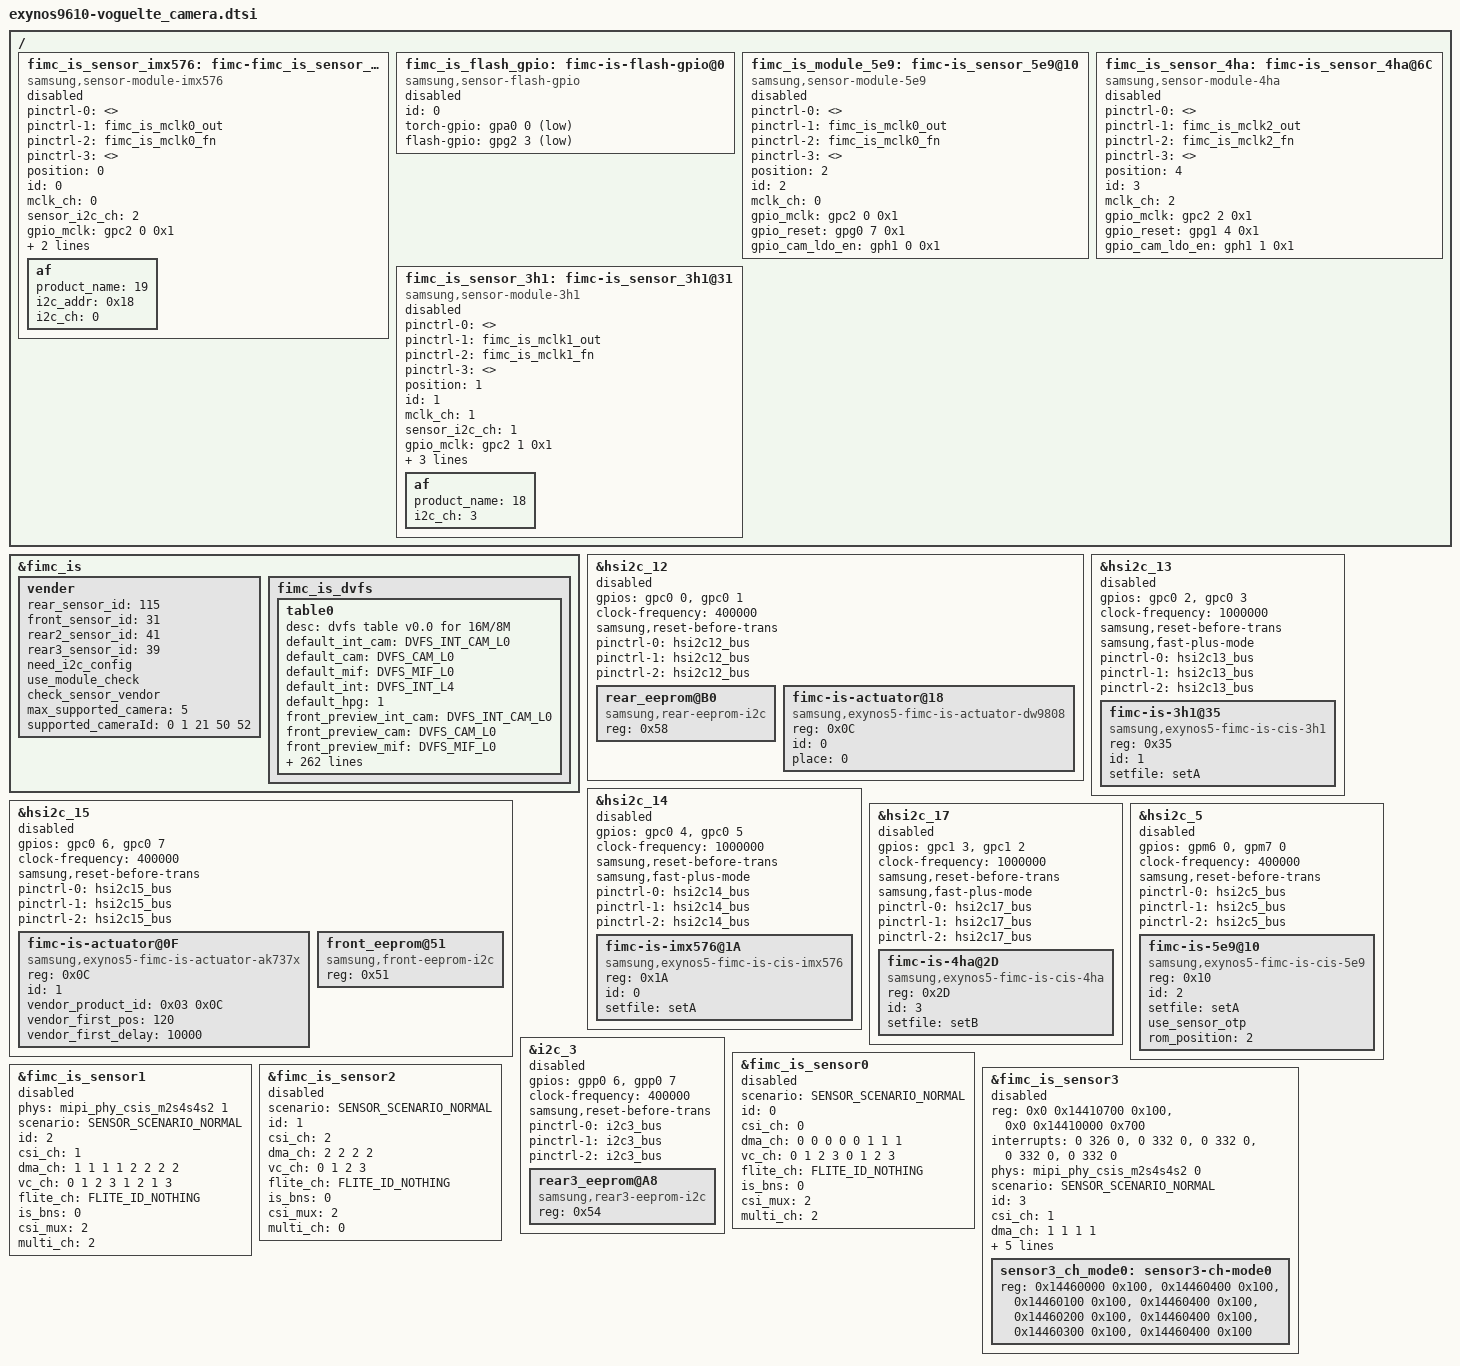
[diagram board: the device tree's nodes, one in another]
/*
 * SAMSUNG EXYNOS9610 board camera device tree source
 *
 * Copyright (c) 2018 Samsung Electronics Co., Ltd.
 *		http://www.samsung.com
 *
 * This program is free software; you can redistribute it and/or modify
 * it under the terms of the GNU General Public License version 2 as
 * published by the Free Software Foundation.
 */

#include <dt-bindings/camera/fimc_is.h>

/ {
	fragment@camera {
		target-path = "/";
		__overlay__ {
			/* REAR CAMERA */
			fimc_is_sensor_imx576: fimc-fimc_is_sensor_imx576@1A {
				compatible = "samsung,sensor-module-imx576";

				pinctrl-names = "pin0", "pin1", "pin2", "release";
				pinctrl-0 = <>;
				pinctrl-1 = <&fimc_is_mclk0_out>;
				pinctrl-2 = <&fimc_is_mclk0_fn>;
				pinctrl-3 = <>;

				position = <0>;	/* Rear:0. Front:1. Rear_sub:2. Secure:3. */
				id = <0>; /* fimc_is_sensor id */
				mclk_ch = <0>;
				sensor_i2c_ch = <2>; /* SENSOR_CONTROL_I2C2 */

				gpio_mclk = <&gpc2 0 0x1>;
				gpio_reset = <&gpg1 1 0x1>; /* sensor reset */
				gpio_camcore_1p05_en = <&gpc1 1 0x1>; /* gpio_camcore_1p05_en */

				status = "disabled";

				af {
					product_name = <19>;			/* ACTUATOR_NAME_DW9808 */
					i2c_addr = <0x18>;
					i2c_ch = <0>;					/* SENSOR_CONTROL_I2C0 */
				};
			};

			fimc_is_flash_gpio: fimc-is-flash-gpio@0 {
				compatible = "samsung,sensor-flash-gpio";
				id = <0>;
				status = "disabled";

				torch-gpio = <&gpa0 0 0x1>;
				flash-gpio = <&gpg2 3 0x1>;
			};

			/* REAR Sub CAMERA */
			fimc_is_module_5e9: fimc-is_sensor_5e9@10 {
				compatible = "samsung,sensor-module-5e9";

				pinctrl-names = "pin0", "pin1", "pin2", "release";
				pinctrl-0 = <>;
				pinctrl-1 = <&fimc_is_mclk0_out>;
				pinctrl-2 = <&fimc_is_mclk0_fn>;
				pinctrl-3 = <>;

				position = <2>;	/* Rear:0. Front:1 */
				id = <2>; /* fimc_is_sensor id */
				mclk_ch = <0>;

				gpio_mclk = <&gpc2 0 0x1>;		/* RCAM1_RCAM2_MCLK */
				gpio_reset = <&gpg0 7 0x1>;		/* RCAM2_RST_N */
				gpio_cam_ldo_en = <&gph1 0 0x1>;	/* RCAM2_LDO_EN  ---> DVDD1P2, AVDD2P8, VDDIO1P8 */
				status = "disabled";
			};

			/* REAR Third CAMERA */
			fimc_is_sensor_4ha: fimc-is_sensor_4ha@6C {
				compatible = "samsung,sensor-module-4ha";

				pinctrl-names = "pin0", "pin1", "pin2", "release";
				pinctrl-0 = <>;
				pinctrl-1 = <&fimc_is_mclk2_out>;
				pinctrl-2 = <&fimc_is_mclk2_fn>;
				pinctrl-3 = <>;

				position = <4>;	/* Rear:0. Front:1 .. Rear3:6*/
				id = <3>;		/* fimc_is_sensor id */
				mclk_ch = <2>;

				gpio_mclk = <&gpc2 2 0x1>;		/* RCAM3_MCLK */
				gpio_reset = <&gpg1 4 0x1>;		/* RCAM3_RST_N */
				gpio_cam_ldo_en = <&gph1 1 0x1>;	/* RCAM3_LDO_EN  ---> DVDD1P2, AVDD2P8, VDDIO1P8 */
				status = "disabled";
			};

			/* FRONT CAMERA */
			fimc_is_sensor_3h1: fimc-is_sensor_3h1@31 {
				compatible = "samsung,sensor-module-3h1";

				pinctrl-names = "pin0", "pin1", "pin2", "release";
				pinctrl-0 = <>;
				pinctrl-1 = <&fimc_is_mclk1_out>;
				pinctrl-2 = <&fimc_is_mclk1_fn>;
				pinctrl-3 = <>;

				position = <1>;	/* Rear:0. Front:1. Rear_sub:2. Secure:3. */
				id = <1>; /* fimc_is_sensor id */
				mclk_ch = <1>;
				sensor_i2c_ch = <1>; /* SENSOR_CONTROL_I2C1 */

				gpio_mclk = <&gpc2 1 0x1>;
				gpio_reset = <&gpg1 7 0x1>; /* sensor reset */
				gpio_cam_ldo_en = <&gpc1 0 0x1>; /* CAM LDO all enable */

				power_seq_id = <1>;
				status = "disabled";

				af {
					product_name = <18>; /* ACTUATOR_NAME_AK737X : ak7372 */
					i2c_ch = <3>; /* SENSOR_CONTROL_I2C3 */
				};

			};

		}; /* end of __overlay__ */
	}; /* end of fragment */
}; /* end of root */

/***** reference symbol node *****/

&fimc_is {
	vender {
		rear_sensor_id = <115>; /* SENSOR_NAME_IMX576 */
		front_sensor_id = <31>; /* SENSOR_NAME_S5K3H1 */
		rear2_sensor_id = <41>; /* SENSOR_NAME_S5K5E9  */
		rear3_sensor_id = <39>;	/* SENSOR_NAME_S5K4HA */
		need_i2c_config;
		use_module_check;
		check_sensor_vendor;
		max_supported_camera = <5>;
		supported_cameraId = <0 1 21 50 52>;
	};

	fimc_is_dvfs {
		#define DVFS_INT_CAM_L0 690000
		#define DVFS_INT_CAM_L1 680000
		#define DVFS_INT_CAM_L2 670000
		#define DVFS_INT_CAM_L3 660000
		#define DVFS_INT_CAM_L4 650000

		#define DVFS_INT_L0 667000
		#define DVFS_INT_L1 533000
		#define DVFS_INT_L2 400000
		#define DVFS_INT_L3 200000
		#define DVFS_INT_L4 100000

		#define DVFS_CAM_L0 690000
		#define DVFS_CAM_L1 680000
		#define DVFS_CAM_L2 670000
		#define DVFS_CAM_L3 660000
		#define DVFS_CAM_L4 650000
		#define DVFS_CAM_L5 640000

		#define DVFS_MIF_L0 2093000
		#define DVFS_MIF_L1 2002000
		#define DVFS_MIF_L2 1794000
		#define DVFS_MIF_L3 1539000
		#define DVFS_MIF_L4 1352000
		#define DVFS_MIF_L5 1014000
		#define DVFS_MIF_L6 845000
		#define DVFS_MIF_L7 676000
		#define DVFS_MIF_L8 546000
		#define DVFS_MIF_L9 419000

		table0 {
			desc = "dvfs table v0.0 for 16M/8M";

			default_int_cam = <DVFS_INT_CAM_L0>;
			default_cam = <DVFS_CAM_L0>;
			default_mif = <DVFS_MIF_L0>;
			default_int = <DVFS_INT_L4>;
			default_hpg = <1>;

			front_preview_int_cam = <DVFS_INT_CAM_L0>;
			front_preview_cam = <DVFS_CAM_L0>;
			front_preview_mif = <DVFS_MIF_L0>;
			front_preview_int = <DVFS_INT_L4>;
			front_preview_hpg = <1>;

			front_preview_full_int_cam = <DVFS_INT_CAM_L0>;
			front_preview_full_cam = <DVFS_CAM_L0>;
			front_preview_full_mif = <DVFS_MIF_L0>;
			front_preview_full_int = <DVFS_INT_L4>;
			front_preview_full_hpg = <1>;

			front_capture_int_cam = <DVFS_INT_CAM_L0>;
			front_capture_cam = <DVFS_CAM_L0>;
			front_capture_mif = <DVFS_MIF_L0>;
			front_capture_int = <DVFS_INT_L4>;
			front_capture_hpg = <1>;

			front_video_int_cam = <DVFS_INT_CAM_L0>;
			front_video_cam = <DVFS_CAM_L0>;
			front_video_mif = <DVFS_MIF_L0>;
			front_video_int = <DVFS_INT_L4>;
			front_video_hpg = <1>;

			front_video_capture_int_cam = <DVFS_INT_CAM_L0>;
			front_video_capture_cam = <DVFS_CAM_L0>;
			front_video_capture_mif = <DVFS_MIF_L0>;
			front_video_capture_int = <DVFS_INT_L4>;
			front_video_capture_hpg = <1>;

			front_wide_selfie_int_cam = <DVFS_INT_CAM_L0>;
			front_wide_selfie_cam = <DVFS_CAM_L0>;
			front_wide_selfie_mif = <DVFS_MIF_L0>;
			front_wide_selfie_int = <DVFS_INT_L4>;
			front_wide_selfie_hpg = <1>;

			front_vt1_int_cam = <DVFS_INT_CAM_L0>;
			front_vt1_cam = <DVFS_CAM_L0>;
			front_vt1_mif = <DVFS_MIF_L0>;
			front_vt1_int = <DVFS_INT_L4>;
			front_vt1_hpg = <1>;

			front_vt2_int_cam = <DVFS_INT_CAM_L0>;
			front_vt2_cam = <DVFS_CAM_L0>;
			front_vt2_mif = <DVFS_MIF_L0>;
			front_vt2_int = <DVFS_INT_L4>;
			front_vt2_hpg = <1>;

			front_vt4_int_cam = <DVFS_INT_CAM_L0>;
			front_vt4_cam = <DVFS_CAM_L0>;
			front_vt4_mif = <DVFS_MIF_L0>;
			front_vt4_int = <DVFS_INT_L4>;
			front_vt4_hpg = <1>;

			rear2_preview_fhd_int_cam = <DVFS_INT_CAM_L0>;
			rear2_preview_fhd_cam = <DVFS_CAM_L0>;
			rear2_preview_fhd_mif = <DVFS_MIF_L0>;
			rear2_preview_fhd_int = <DVFS_INT_L4>;
			rear2_preview_fhd_hpg = <1>;

			rear2_capture_int_cam = <DVFS_INT_CAM_L0>;
			rear2_capture_cam = <DVFS_CAM_L0>;
			rear2_capture_mif = <DVFS_MIF_L0>;
			rear2_capture_int = <DVFS_INT_L4>;
			rear2_capture_hpg = <1>;

			rear2_video_fhd_int_cam = <DVFS_INT_CAM_L0>;
			rear2_video_fhd_cam = <DVFS_CAM_L0>;
			rear2_video_fhd_mif = <DVFS_MIF_L0>;
			rear2_video_fhd_int = <DVFS_INT_L4>;
			rear2_video_fhd_hpg = <1>;

			rear2_video_fhd_capture_int_cam = <DVFS_INT_CAM_L0>;
			rear2_video_fhd_capture_cam = <DVFS_CAM_L0>;
			rear2_video_fhd_capture_mif = <DVFS_MIF_L0>;
			rear2_video_fhd_capture_int = <DVFS_INT_L4>;
			rear2_video_fhd_capture_hpg = <1>;

			rear3_preview_int_cam = <DVFS_INT_CAM_L0>;
			rear3_preview_cam = <DVFS_CAM_L0>;
			rear3_preview_mif = <DVFS_MIF_L0>;
			rear3_preview_int = <DVFS_INT_L4>;
			rear3_preview_hpg = <1>;

			rear3_capture_int_cam = <DVFS_INT_CAM_L0>;
			rear3_capture_cam = <DVFS_CAM_L0>;
			rear3_capture_mif = <DVFS_MIF_L0>;
			rear3_capture_int = <DVFS_INT_L4>;
			rear3_capture_hpg = <1>;

			rear3_video_int_cam = <DVFS_INT_CAM_L0>;
			rear3_video_cam = <DVFS_CAM_L0>;
			rear3_video_mif = <DVFS_MIF_L0>;
			rear3_video_int = <DVFS_INT_L4>;
			rear3_video_hpg = <1>;

			rear_preview_fhd_int_cam = <DVFS_INT_CAM_L0>;
			rear_preview_fhd_cam = <DVFS_CAM_L0>;
			rear_preview_fhd_mif = <DVFS_MIF_L0>;
			rear_preview_fhd_int = <DVFS_INT_L4>;
			rear_preview_fhd_hpg = <1>;

			rear_preview_hd_int_cam = <DVFS_INT_CAM_L0>;
			rear_preview_hd_cam = <DVFS_CAM_L0>;
			rear_preview_hd_mif = <DVFS_MIF_L0>;
			rear_preview_hd_int = <DVFS_INT_L4>;
			rear_preview_hd_hpg = <1>;

			rear_preview_uhd_int_cam = <DVFS_INT_CAM_L0>;
			rear_preview_uhd_cam = <DVFS_CAM_L0>;
			rear_preview_uhd_mif = <DVFS_MIF_L0>;
			rear_preview_uhd_int = <DVFS_INT_L4>;
			rear_preview_uhd_hpg = <1>;

			rear_preview_full_int_cam = <DVFS_INT_CAM_L0>;
			rear_preview_full_cam = <DVFS_CAM_L0>;
			rear_preview_full_mif = <DVFS_MIF_L0>;
			rear_preview_full_int = <DVFS_INT_L4>;
			rear_preview_full_hpg = <1>;

			rear_capture_int_cam = <DVFS_INT_CAM_L0>;
			rear_capture_cam = <DVFS_CAM_L0>;
			rear_capture_mif = <DVFS_MIF_L0>;
			rear_capture_int = <DVFS_INT_L4>;
			rear_capture_hpg = <1>;

			rear_video_fhd_int_cam = <DVFS_INT_CAM_L0>;
			rear_video_fhd_cam = <DVFS_CAM_L0>;
			rear_video_fhd_mif = <DVFS_MIF_L0>;
			rear_video_fhd_int = <DVFS_INT_L4>;
			rear_video_fhd_hpg = <1>;

			rear_video_hd_int_cam = <DVFS_INT_CAM_L0>;
			rear_video_hd_cam = <DVFS_CAM_L0>;
			rear_video_hd_mif = <DVFS_MIF_L0>;
			rear_video_hd_int = <DVFS_INT_L4>;
			rear_video_hd_hpg = <1>;

			rear_video_uhd_int_cam = <DVFS_INT_CAM_L0>;
			rear_video_uhd_cam = <DVFS_CAM_L0>;
			rear_video_uhd_mif = <DVFS_MIF_L0>;
			rear_video_uhd_int = <DVFS_INT_L4>;
			rear_video_uhd_hpg = <1>;

			rear_video_fhd_capture_int_cam = <DVFS_INT_CAM_L0>;
			rear_video_fhd_capture_cam = <DVFS_CAM_L0>;
			rear_video_fhd_capture_mif = <DVFS_MIF_L0>;
			rear_video_fhd_capture_int = <DVFS_INT_L4>;
			rear_video_fhd_capture_hpg = <1>;

			rear_video_hd_capture_int_cam = <DVFS_INT_CAM_L0>;
			rear_video_hd_capture_cam = <DVFS_CAM_L0>;
			rear_video_hd_capture_mif = <DVFS_MIF_L0>;
			rear_video_hd_capture_int = <DVFS_INT_L4>;
			rear_video_hd_capture_hpg = <1>;

			rear_video_uhd_capture_int_cam = <DVFS_INT_CAM_L0>;
			rear_video_uhd_capture_cam = <DVFS_CAM_L0>;
			rear_video_uhd_capture_mif = <DVFS_MIF_L0>;
			rear_video_uhd_capture_int = <DVFS_INT_L4>;
			rear_video_uhd_capture_hpg = <1>;

			dual_preview_int_cam = <DVFS_INT_CAM_L0>;
			dual_preview_cam = <DVFS_CAM_L0>;
			dual_preview_mif = <DVFS_MIF_L0>;
			dual_preview_int = <DVFS_INT_L4>;
			dual_preview_hpg = <1>;

			dual_capture_int_cam = <DVFS_INT_CAM_L0>;
			dual_capture_cam = <DVFS_CAM_L0>;
			dual_capture_mif = <DVFS_MIF_L0>;
			dual_capture_int = <DVFS_INT_L4>;
			dual_capture_hpg = <1>;

			dual_video_fhd_int_cam = <DVFS_INT_CAM_L0>;
			dual_video_fhd_cam = <DVFS_CAM_L0>;
			dual_video_fhd_mif = <DVFS_MIF_L0>;
			dual_video_fhd_int = <DVFS_INT_L4>;
			dual_video_fhd_hpg = <1>;

			dual_video_fhd_capture_int_cam = <DVFS_INT_CAM_L0>;
			dual_video_fhd_capture_cam = <DVFS_CAM_L0>;
			dual_video_fhd_capture_mif = <DVFS_MIF_L0>;
			dual_video_fhd_capture_int = <DVFS_INT_L4>;
			dual_video_fhd_capture_hpg = <1>;

			dual_video_uhd_int_cam = <DVFS_INT_CAM_L0>;
			dual_video_uhd_cam = <DVFS_CAM_L0>;
			dual_video_uhd_mif = <DVFS_MIF_L0>;
			dual_video_uhd_int = <DVFS_INT_L4>;
			dual_video_uhd_hpg = <1>;

			dual_video_uhd_capture_int_cam = <DVFS_INT_CAM_L0>;
			dual_video_uhd_capture_cam = <DVFS_CAM_L0>;
			dual_video_uhd_capture_mif = <DVFS_MIF_L0>;
			dual_video_uhd_capture_int = <DVFS_INT_L4>;
			dual_video_uhd_capture_hpg = <1>;

			dual_sync_preview_int_cam = <DVFS_INT_CAM_L0>;
			dual_sync_preview_cam = <DVFS_CAM_L0>;
			dual_sync_preview_mif = <DVFS_MIF_L0>;
			dual_sync_preview_int = <DVFS_INT_L4>;
			dual_sync_preview_hpg = <1>;

			dual_sync_capture_int_cam = <DVFS_INT_CAM_L0>;
			dual_sync_capture_cam = <DVFS_CAM_L0>;
			dual_sync_capture_mif = <DVFS_MIF_L0>;
			dual_sync_capture_int = <DVFS_INT_L4>;
			dual_sync_capture_hpg = <1>;

			dual_sync_preview_whd_int_cam = <DVFS_INT_CAM_L0>;
			dual_sync_preview_whd_cam = <DVFS_CAM_L0>;
			dual_sync_preview_whd_mif = <DVFS_MIF_L0>;
			dual_sync_preview_whd_int = <DVFS_INT_L4>;
			dual_sync_preview_whd_hpg = <1>;

			dual_sync_whd_capture_int_cam = <DVFS_INT_CAM_L0>;
			dual_sync_whd_capture_cam = <DVFS_CAM_L0>;
			dual_sync_whd_capture_mif = <DVFS_MIF_L0>;
			dual_sync_whd_capture_int = <DVFS_INT_L4>;
			dual_sync_whd_capture_hpg = <1>;

			dual_sync_video_fhd_int_cam = <DVFS_INT_CAM_L0>;
			dual_sync_video_fhd_cam = <DVFS_CAM_L0>;
			dual_sync_video_fhd_mif = <DVFS_MIF_L0>;
			dual_sync_video_fhd_int = <DVFS_INT_L4>;
			dual_sync_video_fhd_hpg = <1>;

			dual_sync_video_fhd_capture_int_cam = <DVFS_INT_CAM_L0>;
			dual_sync_video_fhd_capture_cam = <DVFS_CAM_L0>;
			dual_sync_video_fhd_capture_mif = <DVFS_MIF_L0>;
			dual_sync_video_fhd_capture_int = <DVFS_INT_L4>;
			dual_sync_video_fhd_capture_hpg = <1>;

			dual_sync_video_uhd_int_cam = <DVFS_INT_CAM_L0>;
			dual_sync_video_uhd_cam = <DVFS_CAM_L0>;
			dual_sync_video_uhd_mif = <DVFS_MIF_L0>;
			dual_sync_video_uhd_int = <DVFS_INT_L4>;
			dual_sync_video_uhd_hpg = <1>;

			dual_sync_video_uhd_capture_int_cam = <DVFS_INT_CAM_L0>;
			dual_sync_video_uhd_capture_cam = <DVFS_CAM_L0>;
			dual_sync_video_uhd_capture_mif = <DVFS_MIF_L0>;
			dual_sync_video_uhd_capture_int = <DVFS_INT_L4>;
			dual_sync_video_uhd_capture_hpg = <1>;

			secure_front_int_cam = <DVFS_INT_CAM_L0>;
			secure_front_cam = <DVFS_CAM_L0>;
			secure_front_mif = <DVFS_MIF_L0>;
			secure_front_int = <DVFS_INT_L4>;
			secure_front_hpg = <1>;

			preview_high_speed_fps_int_cam = <DVFS_INT_CAM_L0>;
			preview_high_speed_fps_cam = <DVFS_CAM_L0>;
			preview_high_speed_fps_mif = <DVFS_MIF_L0>;
			preview_high_speed_fps_int = <DVFS_INT_L4>;
			preview_high_speed_fps_hpg = <1>;

			video_high_speed_60fps_int_cam = <DVFS_INT_CAM_L0>;
			video_high_speed_60fps_cam = <DVFS_CAM_L0>;
			video_high_speed_60fps_mif = <DVFS_MIF_L0>;
			video_high_speed_60fps_int = <DVFS_INT_L4>;
			video_high_speed_60fps_hpg = <1>;

			video_high_speed_120fps_int_cam = <DVFS_INT_CAM_L0>;
			video_high_speed_120fps_cam = <DVFS_CAM_L0>;
			video_high_speed_120fps_mif = <DVFS_MIF_L0>;
			video_high_speed_120fps_int = <DVFS_INT_L4>;
			video_high_speed_120fps_hpg = <1>;

			video_high_speed_480fps_int_cam = <DVFS_INT_CAM_L0>;
			video_high_speed_480fps_cam = <DVFS_CAM_L0>;
			video_high_speed_480fps_mif = <DVFS_MIF_L0>;
			video_high_speed_480fps_int = <DVFS_INT_L0>;
			video_high_speed_480fps_hpg = <1>;

			video_high_speed_60fps_capture_int_cam = <DVFS_INT_CAM_L0>;
			video_high_speed_60fps_capture_cam = <DVFS_CAM_L0>;
			video_high_speed_60fps_capture_mif = <DVFS_MIF_L0>;
			video_high_speed_60fps_capture_int = <DVFS_INT_L4>;
			video_high_speed_60fps_capture_hpg = <1>;

			ext_front_int_cam = <DVFS_INT_CAM_L0>;
			ext_front_cam = <DVFS_CAM_L0>;
			ext_front_mif = <DVFS_MIF_L0>;
			ext_front_int = <DVFS_INT_L4>;
			ext_front_hpg = <1>;

			ext_secure_int_cam = <DVFS_INT_CAM_L0>;
			ext_secure_cam = <DVFS_CAM_L0>;
			ext_secure_mif = <DVFS_MIF_L0>;
			ext_secure_int = <DVFS_INT_L4>;
			ext_secure_hpg = <1>;

			max_int_cam = <DVFS_INT_CAM_L0>;
			max_cam = <DVFS_CAM_L0>;
			max_mif = <DVFS_MIF_L0>;
			max_int = <DVFS_INT_L0>;
			max_hpg = <1>;
		};
	};
};

/* I2C_CAM0 */ /* SENSOR_CONTROL_I2C0 */
&hsi2c_12 {
	#address-cells = <1>;
	#size-cells = <0>;
	gpios = <&gpc0 0 0 &gpc0 1 0>;
	status = "disabled";
	clock-frequency = <400000>;
	samsung,reset-before-trans;

	pinctrl-names = "default","on_i2c","off_i2c";
	pinctrl-0 = <&hsi2c12_bus>;
	pinctrl-1 = <&hsi2c12_bus>;
	pinctrl-2 = <&hsi2c12_bus>;

	rear_eeprom@B0 {
		compatible = "samsung,rear-eeprom-i2c";
		reg = <0x58>;		/* 7bit-addr */
	};

	fimc-is-actuator@18 {
		compatible = "samsung,exynos5-fimc-is-actuator-dw9808";
		reg = <0x0C>;
		id = <0>;			/* matching sensor id */
		place = <0>;
	};
};

/* I2C_CAM1 */ /* SENSOR_CONTROL_I2C1 */
&hsi2c_13 {
	#address-cells = <1>;
	#size-cells = <0>;
	gpios = <&gpc0 2 0 &gpc0 3 0>;
	status = "disabled";
	clock-frequency = <1000000>;
	samsung,reset-before-trans;
	samsung,fast-plus-mode;

	pinctrl-names = "default","on_i2c","off_i2c";
	pinctrl-0 = <&hsi2c13_bus>;
	pinctrl-1 = <&hsi2c13_bus>;
	pinctrl-2 = <&hsi2c13_bus>;
	
	fimc-is-3h1@35 {
		compatible = "samsung,exynos5-fimc-is-cis-3h1";
		reg = <0x35>; /* 1 bit right shift */
		id = <1>; /* matching fimc_is_sensor id */
		setfile = "setA";
	};
};

/* I2C_CAM2 */ /* SENSOR_CONTROL_I2C2 */
&hsi2c_14 {
	#address-cells = <1>;
	#size-cells = <0>;
	gpios = <&gpc0 4 0 &gpc0 5 0>;
	status = "disabled";
	clock-frequency = <1000000>;
	samsung,reset-before-trans;
	samsung,fast-plus-mode;

	pinctrl-names = "default","on_i2c","off_i2c";
	pinctrl-0 = <&hsi2c14_bus>;
	pinctrl-1 = <&hsi2c14_bus>;
	pinctrl-2 = <&hsi2c14_bus>;

	fimc-is-imx576@1A {
		compatible = "samsung,exynos5-fimc-is-cis-imx576";
		reg = <0x1A>; /* 1 bit right shift */
		id = <0>; /* matching fimc_is_sensor id */
		setfile = "setA";
	};
};

/* I2C_CAM3 */ /* SENSOR_CONTROL_I2C3 */
&hsi2c_15 {
	#address-cells = <1>;
	#size-cells = <0>;
	gpios = <&gpc0 6 0 &gpc0 7 0>;
	status = "disabled";
	clock-frequency = <400000>;
	samsung,reset-before-trans;

	pinctrl-names = "default","on_i2c","off_i2c";
	pinctrl-0 = <&hsi2c15_bus>;
	pinctrl-1 = <&hsi2c15_bus>;
	pinctrl-2 = <&hsi2c15_bus>;

	fimc-is-actuator@0F {
		compatible = "samsung,exynos5-fimc-is-actuator-ak737x";
		reg = <0x0C>; /* 1 bit right shift */
		id = <1>; /* matching fimc_is_sensor id */
		/* AK7372: addr 0x03, data 0x0C */
		/* AK7371: addr 0x03, data 0x09 */
		vendor_product_id = <0x03 0x0C>;
		vendor_first_pos = <120>;
		vendor_first_delay = <10000>;
	};

	front_eeprom@51 {
		compatible = "samsung,front-eeprom-i2c";
		reg = <0x51>;
	};
};

/* USI_PERI_USI_0_I2C */
&hsi2c_17 {
	#address-cells = <1>;
	#size-cells = <0>;
	gpios = <&gpc1 3 0 &gpc1 2 0>;
	status = "disabled";
	clock-frequency = <1000000>;
	samsung,reset-before-trans;
	samsung,fast-plus-mode;

	pinctrl-names = "default","on_i2c","off_i2c";
	pinctrl-0 = <&hsi2c17_bus>;
	pinctrl-1 = <&hsi2c17_bus>;
	pinctrl-2 = <&hsi2c17_bus>;

	fimc-is-4ha@2D {
		compatible = "samsung,exynos5-fimc-is-cis-4ha";
		reg = <0x2D>; /* 1 bit right shift */
		id = <3>; /* matching fimc_is_sensor id */
		setfile = "setB";
	};
};

/* USI_1_CMGP_I2C */
&hsi2c_5 {
	#address-cells = <1>;
	#size-cells = <0>;
	gpios = <&gpm6 0 0 &gpm7 0 0>;
	status = "disabled";
	clock-frequency = <400000>;
	samsung,reset-before-trans;

	pinctrl-names = "default","on_i2c","off_i2c";
	pinctrl-0 = <&hsi2c5_bus>;
	pinctrl-1 = <&hsi2c5_bus>;
	pinctrl-2 = <&hsi2c5_bus>;

	fimc-is-5e9@10 {
		compatible = "samsung,exynos5-fimc-is-cis-5e9";
		reg = <0x10>; /* 1 bit right shift */
		id = <2>; /* matching fimc_is_sensor id */
		setfile = "setA";

		use_sensor_otp;			/* USE OTP CAL MAP */
		rom_position = <2>;		/* SENSOR_POSITION_REAR2 */
	};
};

&i2c_3 {
	#address-cells = <1>;
	#size-cells = <0>;
	gpios = <&gpp0 6 0 &gpp0 7 0>;
	status = "disabled";
	clock-frequency = <400000>;
	samsung,reset-before-trans;

	pinctrl-names = "default","on_i2c","off_i2c";
	pinctrl-0 = <&i2c3_bus>;
	pinctrl-1 = <&i2c3_bus>;
	pinctrl-2 = <&i2c3_bus>;

	rear3_eeprom@A8 {
		compatible = "samsung,rear3-eeprom-i2c";
		reg = <0x54>;		/* 7bit-addr */
	};
};

&fimc_is_sensor0 {
	scenario = <SENSOR_SCENARIO_NORMAL>;	/* Normal, Vision, OIS etc */
	id = <0>;
	csi_ch = <0>;
	dma_ch = <0 0 0 0 0 1 1 1>;
	vc_ch = <0 1 2 3 0 1 2 3>;
	flite_ch = <FLITE_ID_NOTHING>;
	is_bns = <0>;
	csi_mux = <2>;	/* CSIS_DPHY[2:0] = [0 1 0] */
	multi_ch = <2>;
	/* use_ssvc1_internal; */
	/* use_ssvc2_internal; */
	status = "disabled";
};

&fimc_is_sensor1 {
	phys = <&mipi_phy_csis_m2s4s4s2 1>;

	scenario = <SENSOR_SCENARIO_NORMAL>;	/* Normal, Vision, OIS etc */
	id = <2>;
	csi_ch = <1>;
	dma_ch = <1 1 1 1 2 2 2 2>;
	vc_ch = <0 1 2 3 1 2 1 3>;
	flite_ch = <FLITE_ID_NOTHING>;
	is_bns = <0>;
	csi_mux = <2>;	/* CSIS_DPHY[2:0] = [0 1 0] */
	multi_ch = <2>;
	status = "disabled";
};

&fimc_is_sensor2 {
	scenario = <SENSOR_SCENARIO_NORMAL>;	/* Normal, Vision, OIS etc */
	id = <1>;
	csi_ch = <2>;
	dma_ch = <2 2 2 2>;
	vc_ch = <0 1 2 3>;
	flite_ch = <FLITE_ID_NOTHING>;
	is_bns = <0>;
	csi_mux = <2>;	/* CSIS_DPHY[2:0] = [0 1 0] */
	multi_ch = <0>;
	status = "disabled";
};

&fimc_is_sensor3 {
	reg = <0x0 0x14410700 0x100>, /* PHY: TOP_M2S4S4S2 */
		<0x0 0x14410000 0x700>; /* MIPI-CSI0 */
	reg-names = "phy", "csi";
	interrupts = <0 326 0>, /* MIPI-CSI1 */
		<0 332 0>, /* VC0 DMA1 */
		<0 332 0>, /* VC1 DMA1 */
		<0 332 0>, /* VC2 DMA1 */
		<0 332 0>; /* VC3 DMA1 */
	interrupt-names = "csi",
		"mode0_VC0", "mode0_VC1","mode0_VC2","mode0_VC3";
	phys = <&mipi_phy_csis_m2s4s4s2 0>;

	scenario = <SENSOR_SCENARIO_NORMAL>;	/* Normal, Vision, OIS etc */
	id = <3>;
	csi_ch = <1>;
	dma_ch = <1 1 1 1>;
	vc_ch = <0 1 2 3>;
	flite_ch = <FLITE_ID_NOTHING>;
	is_bns = <0>;
	csi_mux = <0>;	/* CSIS_DPHY[2:0] = [0 0 0] */
	multi_ch = <2>;
	status = "disabled";

	/* without PAF HW */
	sensor3_ch_mode0: sensor3-ch-mode0 {
		reg = <0x14460000 0x100>, /* VC0 DMA1 */
			<0x14460400 0x100>, /* VC0 DMA1 COMMON */
			<0x14460100 0x100>, /* VC1 DMA1 */
			<0x14460400 0x100>, /* VC1 DMA1 COMMON */
			<0x14460200 0x100>, /* VC2 DMA1 */
			<0x14460400 0x100>, /* VC2 DMA1 COMMON */
			<0x14460300 0x100>, /* VC3 DMA1 */
			<0x14460400 0x100>; /* VC3 DMA1 COMMON */
	};	
};
